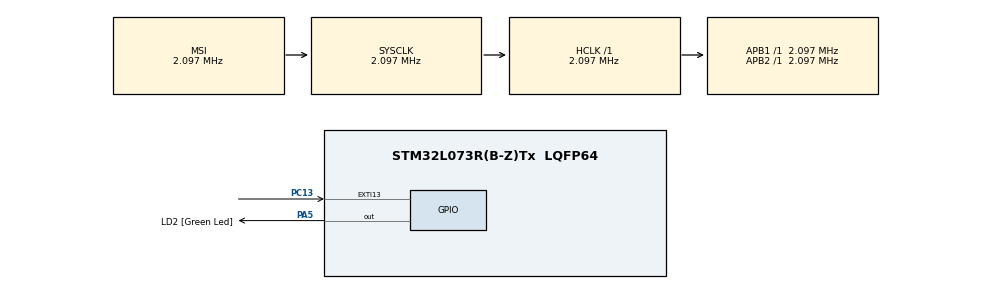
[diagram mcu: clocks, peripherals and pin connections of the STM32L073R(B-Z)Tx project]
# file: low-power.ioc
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Mcu.Family=STM32L0
Mcu.Name=STM32L073R(B-Z)Tx
Mcu.Package=LQFP64
NVIC.EXTI4_15_IRQn=true\:0\:0\:false\:false\:true\:true\:true\:true
PA0.Mode=SYS_WakeUp0
PA0.Signal=SYS_WKUP1
PA13.GPIO_Label=TMS
PA13.Mode=Serial_Wire
PA13.Signal=SYS_SWDIO
PA14.GPIO_Label=TCK
PA14.Mode=Serial_Wire
PA14.Signal=SYS_SWCLK
PA5.GPIO_Label=LD2 [Green Led]
PA5.Signal=GPIO_Output
PC13.GPIO_PuPd=GPIO_PULLUP
PC13.Signal=GPXTI13
ProjectManager.HeapSize=0x200
ProjectManager.StackSize=0x400
ProjectManager.TargetToolchain=STM32CubeIDE
RCC.AHBFreq_Value=2097000
RCC.APB1Freq_Value=2097000
RCC.APB1TimFreq_Value=2097000
RCC.APB2Freq_Value=2097000
RCC.APB2TimFreq_Value=2097000
RCC.HSE_VALUE=8000000
RCC.HSI16_VALUE=16000000
RCC.HSI48_VALUE=48000000
RCC.HSI_VALUE=16000000
RCC.LSE_VALUE=32768
RCC.MSI_VALUE=2097000
RCC.PWR_Regulator_Voltage_Scale=PWR_REGULATOR_VOLTAGE_SCALE3
RCC.SYSCLKFreq_VALUE=2097000
RCC.VCOOutputFreq_Value=48000000
board=NUCLEO-L073RZ

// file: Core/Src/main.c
/* USER CODE BEGIN Header */
/**
  ******************************************************************************
  * @file           : main.c
  * @brief          : Main program body
  ******************************************************************************
  * @attention
  *
  * Copyright (c) 2023 STMicroelectronics.
  * All rights reserved.
  *
  * This software is licensed under terms that can be found in the LICENSE file
  * in the root directory of this software component.
  * If no LICENSE file comes with this software, it is provided AS-IS.
  *
  ******************************************************************************
  */
/* USER CODE END Header */
#include "main.h"
#include "gpio.h"

void SystemClock_Config(void);
/* USER CODE BEGIN PFP */

/**
  * @brief  System Power Configuration
  *         The system Power is configured as follow :
  *            + VREFINT OFF, with fast wakeup enabled
  *            + No IWDG
  *            + Wakeup using PWR_WAKEUP_PIN2
  * @param None
  * @retval None
  */
static void SystemPower_Config(void)
{
  /* Enable Power Control clock */
  __HAL_RCC_PWR_CLK_ENABLE();

  /* Enable Ultra low power mode */
  HAL_PWREx_EnableUltraLowPower();

  /* Enable the fast wake up from Ultra low power mode */
  HAL_PWREx_EnableFastWakeUp();
}

/* USER CODE END PFP */

int main(void)
{

  /* MCU Configuration--------------------------------------------------------*/

  /* Reset of all peripherals, Initializes the Flash interface and the Systick. */
  HAL_Init();

  /* Configure the system clock */
  SystemClock_Config();

  /* Initialize all configured peripherals */
  MX_GPIO_Init();
  /* USER CODE BEGIN 2 */

  /* Configure the system Power */
   SystemPower_Config();

   /* Check and handle if the system was resumed from Standby mode */
   if (__HAL_PWR_GET_FLAG(PWR_FLAG_SB) != RESET)
   {
     /* Clear Standby flag */
     __HAL_PWR_CLEAR_FLAG(PWR_FLAG_SB);
   }

   HAL_GPIO_WritePin(GPIOA, GPIO_PIN_5, 1);

   /* Insert 5 seconds delay */
   HAL_Delay(1000);

   HAL_GPIO_WritePin(GPIOA, GPIO_PIN_5, 0);

   HAL_Delay(1000);
   led_analog();

   /* The Following Wakeup sequence is highly recommended prior to each Standby mode entry
      mainly when using more than one wakeup source this is to not miss any wakeup event.
       - Disable all used wakeup sources,
       - Clear all related wakeup flags,
       - Re-enable all used wakeup sources,
       - Enter the Standby mode.
    */

    /* Disable all used wakeup sources: PWR_WAKEUP_PIN1 */
    HAL_PWR_DisableWakeUpPin(PWR_WAKEUP_PIN1);

    /* Clear all related wakeup flags*/
    __HAL_PWR_CLEAR_FLAG(PWR_FLAG_WU);

    /* Enable WakeUp Pin PWR_WAKEUP_PIN2 connected to PC.13 */
    HAL_PWR_EnableWakeUpPin(PWR_WAKEUP_PIN1);

    /* Enter the Standby mode */
    HAL_PWR_EnterSTANDBYMode();

  /* USER CODE END 2 */

  /* Infinite loop */
  while (1)
  {

  }
}

void SystemClock_Config(void)
{
  RCC_OscInitTypeDef RCC_OscInitStruct = {0};
  RCC_ClkInitTypeDef RCC_ClkInitStruct = {0};

  /** Configure the main internal regulator output voltage
  */
  __HAL_PWR_VOLTAGESCALING_CONFIG(PWR_REGULATOR_VOLTAGE_SCALE3);

  /** Initializes the RCC Oscillators according to the specified parameters
  * in the RCC_OscInitTypeDef structure.
  */
  RCC_OscInitStruct.OscillatorType = RCC_OSCILLATORTYPE_MSI;
  RCC_OscInitStruct.MSIState = RCC_MSI_ON;
  RCC_OscInitStruct.MSICalibrationValue = 0;
  RCC_OscInitStruct.MSIClockRange = RCC_MSIRANGE_5;
  RCC_OscInitStruct.PLL.PLLState = RCC_PLL_NONE;
  if (HAL_RCC_OscConfig(&RCC_OscInitStruct) != HAL_OK)
  {
    Error_Handler();
  }

  /** Initializes the CPU, AHB and APB buses clocks
  */
  RCC_ClkInitStruct.ClockType = RCC_CLOCKTYPE_HCLK|RCC_CLOCKTYPE_SYSCLK
                              |RCC_CLOCKTYPE_PCLK1|RCC_CLOCKTYPE_PCLK2;
  RCC_ClkInitStruct.SYSCLKSource = RCC_SYSCLKSOURCE_MSI;
  RCC_ClkInitStruct.AHBCLKDivider = RCC_SYSCLK_DIV1;
  RCC_ClkInitStruct.APB1CLKDivider = RCC_HCLK_DIV1;
  RCC_ClkInitStruct.APB2CLKDivider = RCC_HCLK_DIV1;

  if (HAL_RCC_ClockConfig(&RCC_ClkInitStruct, FLASH_LATENCY_0) != HAL_OK)
  {
    Error_Handler();
  }
}

void Error_Handler(void)
{
  __disable_irq();
  while (1)
  {
  }
}
